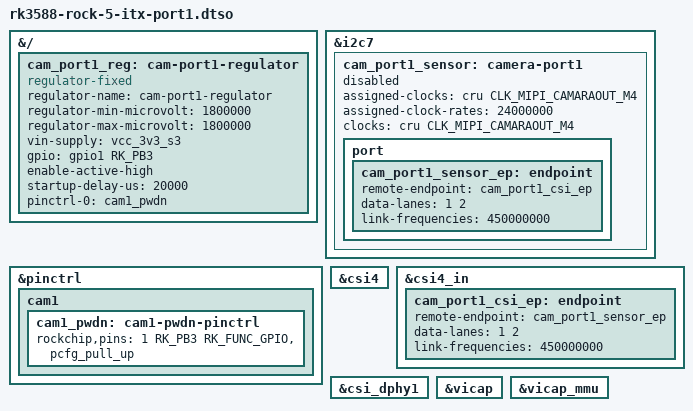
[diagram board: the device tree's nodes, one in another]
// SPDX-License-Identifier: (GPL-2.0+ OR MIT)
/*
 * ROCK 5 ITX CAM1 (port1): Inno CSI D-PHY1 + CSI4 on i2c7.
 *
 * Publishes cam_port1_sensor, cam_port1_sensor_ep, cam_port1_csi_ep,
 * and cam_port1_reg. The sensor node stays disabled until a sensor overlay
 * enables it.
 *
 * Connector data is from Radxa's overlays. The connector's power-down line
 * (gpio1 PB3) enables the module: it is the enable of cam_port1_reg, which
 * the sensor overlays use as their supply, so it goes high when the sensor
 * powers up. The clock is the SoC's camera output at 24 MHz without a pin mux:
 * Raspberry Pi style modules carry their own oscillator.
 */

/dts-v1/;
/plugin/;

#include <dt-bindings/clock/rockchip,rk3588-cru.h>
#include <dt-bindings/gpio/gpio.h>
#include <dt-bindings/pinctrl/rockchip.h>

&{/} {
	cam_port1_reg: cam-port1-regulator {
		compatible = "regulator-fixed";
		regulator-name = "cam-port1-regulator";
		regulator-min-microvolt = <1800000>;
		regulator-max-microvolt = <1800000>;
		vin-supply = <&vcc_3v3_s3>;
		gpio = <&gpio1 RK_PB3 GPIO_ACTIVE_HIGH>;
		enable-active-high;
		startup-delay-us = <20000>;
		pinctrl-names = "default";
		pinctrl-0 = <&cam1_pwdn>;
	};
};

&i2c7 {
	#address-cells = <1>;
	#size-cells = <0>;
	status = "okay";

	cam_port1_sensor: camera-port1 {
		status = "disabled";
		assigned-clocks = <&cru CLK_MIPI_CAMARAOUT_M4>;
		assigned-clock-rates = <24000000>;
		clocks = <&cru CLK_MIPI_CAMARAOUT_M4>;

		port {
			cam_port1_sensor_ep: endpoint {
				remote-endpoint = <&cam_port1_csi_ep>;
				data-lanes = <1 2>;
				link-frequencies = /bits/ 64 <450000000>;
			};
		};
	};
};

&pinctrl {
	cam1 {
		cam1_pwdn: cam1-pwdn-pinctrl {
			rockchip,pins = <1 RK_PB3 RK_FUNC_GPIO &pcfg_pull_up>;
		};
	};
};

&csi4 {
	status = "okay";
};

&csi4_in {
	cam_port1_csi_ep: endpoint {
		remote-endpoint = <&cam_port1_sensor_ep>;
		data-lanes = <1 2>;
		link-frequencies = /bits/ 64 <450000000>;
	};
};

&csi_dphy1 {
	status = "okay";
};

&vicap {
	status = "okay";
};

&vicap_mmu {
	status = "okay";
};
